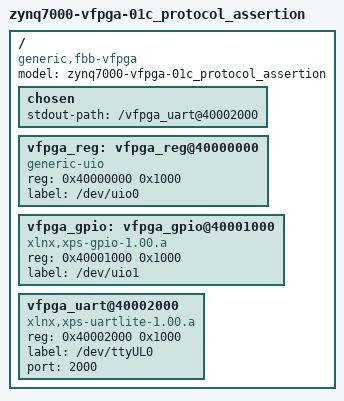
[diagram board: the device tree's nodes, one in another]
/dts-v1/;

/ {
    #address-cells = <1>;
    #size-cells = <1>;
    model = "zynq7000-vfpga-01c_protocol_assertion";
    compatible = "generic,fbb-vfpga";

    chosen {
        stdout-path = "/vfpga_uart@40002000";
    };

    vfpga_reg: vfpga_reg@40000000 {
        compatible = "generic-uio";
        reg = <0x40000000 0x1000>;
        label = "/dev/uio0";
        status = "okay";

    };

    vfpga_gpio: vfpga_gpio@40001000 {
        compatible = "xlnx,xps-gpio-1.00.a";
        reg = <0x40001000 0x1000>;
        label = "/dev/uio1";
        status = "okay";

    };

    vfpga_uart@40002000 {
        compatible = "xlnx,xps-uartlite-1.00.a";
        reg = <0x40002000 0x1000>;
        label = "/dev/ttyUL0";
        port = <2000>;
    };
};
